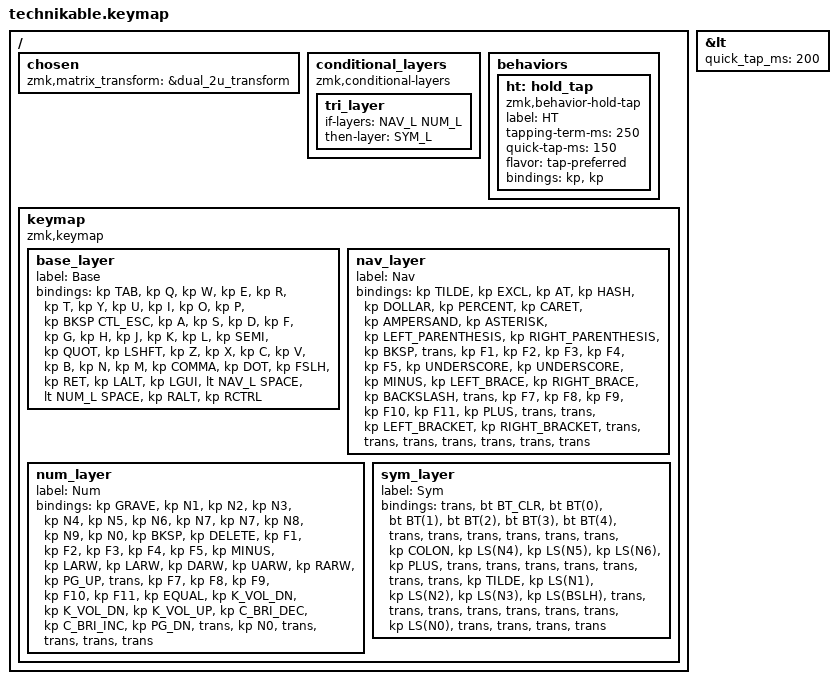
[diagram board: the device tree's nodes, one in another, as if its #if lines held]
/*
 * Copyright (c) 2022 Pete Johanson
 *
 * SPDX-License-Identifier: MIT
 */

#include <behaviors.dtsi>
#include <dt-bindings/zmk/keys.h>
#include <dt-bindings/zmk/bt.h>
#include <dt-bindings/zmk/outputs.h>

#define QWERTY_BASE 1

#define TBLE_ORTHO   true
// #define TBLE_MIT     true
// #define TBLE_DUAL_2U true

//Mod Tap Aliases
#define CMD_BSP &mt LGUI BSPC
#define CTL_BSP &mt LCTL BSPC
#define SFT_ENT &mt LSHFT RET
#define CTL_ESC &mt LCTL ESC

#define BAS_L 0
#define NAV_L 1
#define NUM_L 2
#define SYM_L 3

// Using layer taps on thumbs, having quick tap as well helps w/ repeating space/backspace
&lt { quick_tap_ms = <200>; };

#define BT(n) BT_SEL n

/ {
    chosen {
       zmk,matrix_transform =
#ifdef TBLE_DUAL_2U
                       &dual_2u_transform;
#elif defined(TBLE_MIT)
                       &mit_transform;
#else
                       &ortho_transform;
#endif
    };

    conditional_layers {
        compatible = "zmk,conditional-layers";
	tri_layer {
	    if-layers = <NAV_L NUM_L>;
	    then-layer = <SYM_L>;
	};
    };
    
    behaviors {
	    ht: hold_tap {
	            compatible = "zmk,behavior-hold-tap";
	            label = "HT";
	            #binding-cells = <2>;
	            tapping-term-ms = <250>;
	            quick-tap-ms = <150>;
	            flavor = "tap-preferred";
	            bindings = <&kp>, <&kp>;
	    };
		};
    keymap {
        compatible = "zmk,keymap";

        base_layer {
            label = "Base";
            bindings = <
#ifdef QWERTY_BASE
&kp TAB      &kp Q      &kp W      &kp E      &kp R      &kp T      &kp Y      &kp U      &kp I      &kp O      &kp P      &kp BKSP
CTL_ESC      &kp A      &kp S      &kp D      &kp F      &kp G      &kp H      &kp J      &kp K      &kp L      &kp SEMI      &kp QUOT
&kp LSHFT      &kp Z      &kp X      &kp C      &kp V      &kp B      &kp N      &kp M      &kp COMMA      &kp DOT      &kp FSLH      &kp RET
#else
&kp TAB      &kp Q      &kp W      &kp E      &kp R      &kp T      &kp Y      &kp U      &kp I      &kp O      &kp P      &kp BKSP
CTL_ESC      &kp A      &kp S      &kp D      &kp F      &kp G      &kp H      &kp J      &kp K      &kp L      &kp SEMI      &kp QUOT
&kp LSHFT      &kp Z      &kp X      &kp C      &kp V      &kp B      &kp N      &kp M      &kp COMMA      &kp DOT      &kp FSLH      &kp RET
#endif
#ifdef TBLE_DUAL_2U
                       &kp LALT  &kp LGUI      &lt NAV_L SPACE                &lt NUM_L SPACE              &kp RALT    &kp RCTRL
#elif defined(TBLE_MIT)
                       &kp LALT  &kp LGUI    &mo NAV_L          &kp SPACE                   &mo NUM_L      &kp RALT    &kp RCTRL
#else
                       &kp LALT      &kp LGUI      &mo NAV_L      &kp SPACE      &kp SPACE      &mo NUM_L      &kp RALT      &kp RCTRL            
#endif
            >;
        };

        nav_layer {
            label = "Nav";
            bindings = <
&kp TILDE      &kp EXCL      &kp AT      &kp HASH      &kp DOLLAR      &kp PERCENT      &kp CARET      &kp AMPERSAND      &kp ASTERISK      &kp LEFT_PARENTHESIS      &kp RIGHT_PARENTHESIS      &kp BKSP
&trans      &kp F1      &kp F2      &kp F3      &kp F4      &kp F5      &kp UNDERSCORE      &kp UNDERSCORE      &kp MINUS      &kp LEFT_BRACE      &kp RIGHT_BRACE      &kp BACKSLASH
&trans      &kp F7      &kp F8      &kp F9      &kp F10      &kp F11      &kp PLUS      &trans      &trans      &kp LEFT_BRACKET      &kp RIGHT_BRACKET      &trans
#ifdef TBLE_DUAL_2U
                      &trans     &trans              &trans                    &trans       &trans         &trans
#elif defined(TBLE_MIT)
                      &trans     &trans      &trans                &trans             &trans      &trans   &trans
#else
                      &trans      &kp N0      &trans      &none      &none      &kp ESC      &kp DEL      &trans                   
#endif
            >;
        };

        num_layer {
            label = "Num";
            bindings = <
&kp GRAVE      &kp N1      &kp N2      &kp N3      &kp N4      &kp N5      &kp N6      &kp N7      &kp N7      &kp N8      &kp N9      &kp N0      &kp BKSP
&kp DELETE      &kp F1      &kp F2      &kp F3      &kp F4      &kp F5      &kp MINUS      &kp LARW      &kp LARW      &kp DARW      &kp UARW      &kp RARW      &kp PG_UP
&trans      &kp F7      &kp F8      &kp F9      &kp F10      &kp F11      &kp EQUAL      &kp K_VOL_DN      &kp K_VOL_DN      &kp K_VOL_UP      &kp C_BRI_DEC       &kp C_BRI_INC      &kp PG_DN
#ifdef TBLE_DUAL_2U
                     &trans     &kp N0              &trans                 &trans            &trans         &trans
#elif defined(TBLE_MIT)
                     &trans     &kp N0      &trans           &none            &kp ESC        &kp DEL      &trans
#else
                     &trans      &trans      &trans      &trans      &trans      &trans      &trans      &trans      &trans            
#endif
            >;
        };

        sym_layer {
            label = "Sym";
            bindings = <
&trans      &bt BT_CLR      &bt BT(0)      &bt BT(1)      &bt BT(2)      &bt BT(3)      &bt BT(4)      &trans      &trans      &trans      &trans      &trans
&trans      &kp COLON      &kp LS(N4)      &kp LS(N5)      &kp LS(N6)      &kp PLUS      &trans      &trans      &trans      &trans      &trans      &trans
&trans      &kp TILDE      &kp LS(N1)      &kp LS(N2)      &kp LS(N3)      &kp LS(BSLH)      &trans      &trans      &trans      &trans      &trans      &trans
#ifdef TBLE_DUAL_2U
                      &trans     &kp LS(N0)              &trans                    &trans       &trans         &trans
#elif defined(TBLE_MIT)
                      &trans     &kp LS(N0)      &trans                &trans             &trans      &trans   &trans
#else
                      &trans      kp LS(N0)      &trans      &trans      &trans      &trans      &trans      &trans            
#endif
            >;
        };

    };
};

